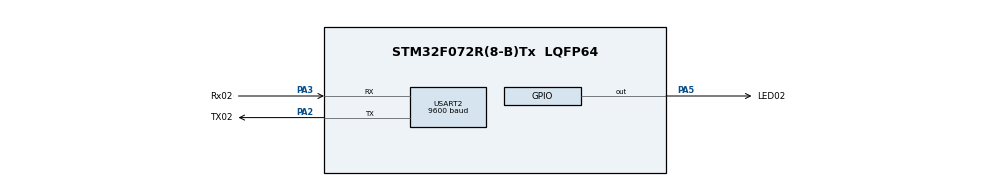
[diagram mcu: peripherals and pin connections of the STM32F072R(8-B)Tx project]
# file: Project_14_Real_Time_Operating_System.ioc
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FREERTOS.Tasks01=Blink01,24,128,StartBlink01,Default,NULL,Dynamic,NULL,NULL;Blink02,16,128,StartBlink02,Default,NULL,Dynamic,NULL,NULL
Mcu.Family=STM32F0
Mcu.Name=STM32F072R(8-B)Tx
Mcu.Package=LQFP64
NVIC.TIM6_DAC_IRQn=true\:3\:0\:false\:false\:true\:false\:false\:true\:true
NVIC.TimeBase=TIM6_DAC_IRQn
NVIC.TimeBaseIP=TIM6
PA2.GPIO_Label=TX02
PA2.Mode=Asynchronous
PA2.Signal=USART2_TX
PA3.GPIO_Label=Rx02
PA3.Mode=Asynchronous
PA3.Signal=USART2_RX
PA5.GPIO_Label=LED02
PA5.Signal=GPIO_Output
ProjectManager.HeapSize=0x200
ProjectManager.StackSize=0x400
ProjectManager.TargetToolchain=STM32CubeIDE
USART2.BaudRate=9600
USART2.VirtualMode-Asynchronous=VM_ASYNC
VP_FREERTOS_VS_CMSIS_V2.Mode=CMSIS_V2
VP_SYS_VS_tim6.Mode=TIM6
board=custom

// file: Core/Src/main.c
/* USER CODE BEGIN Header */
/**
  ******************************************************************************
  * @file           : main.c
  * @brief          : Main program body
  ******************************************************************************
  * @attention
  *
  * Copyright (c) 2022 STMicroelectronics.
  * All rights reserved.
  *
  * This software is licensed under terms that can be found in the LICENSE file
  * in the root directory of this software component.
  * If no LICENSE file comes with this software, it is provided AS-IS.
  *
  ******************************************************************************
  */
/* USER CODE END Header */
#include "main.h"
#include "cmsis_os.h"

UART_HandleTypeDef huart2;

/* Definitions for Blink01 */
osThreadId_t Blink01Handle;
const osThreadAttr_t Blink01_attributes = {
  .name = "Blink01",
  .stack_size = 128 * 4,
  .priority = (osPriority_t) osPriorityNormal,
};
/* Definitions for Blink02 */
osThreadId_t Blink02Handle;
const osThreadAttr_t Blink02_attributes = {
  .name = "Blink02",
  .stack_size = 128 * 4,
  .priority = (osPriority_t) osPriorityBelowNormal,
};

void SystemClock_Config(void);
static void MX_GPIO_Init(void);
static void MX_USART2_UART_Init(void);
void StartBlink01(void *argument);
void StartBlink02(void *argument);

/* USER CODE BEGIN PFP */

void Task_action(char message);

/* USER CODE END PFP */

int main(void)
{

  /* MCU Configuration--------------------------------------------------------*/

  /* Reset of all peripherals, Initializes the Flash interface and the Systick. */
  HAL_Init();

  /* Configure the system clock */
  SystemClock_Config();

  /* Initialize all configured peripherals */
  MX_GPIO_Init();
  MX_USART2_UART_Init();

  /* Init scheduler */
  osKernelInitialize();

  /* Create the thread(s) */
  /* creation of Blink01 */
  Blink01Handle = osThreadNew(StartBlink01, NULL, &Blink01_attributes);

  /* creation of Blink02 */
  Blink02Handle = osThreadNew(StartBlink02, NULL, &Blink02_attributes);

  /* Start scheduler */
  osKernelStart();

  /* We should never get here as control is now taken by the scheduler */
  /* Infinite loop */
  while (1)
  {

  }
}

void SystemClock_Config(void)
{
  RCC_OscInitTypeDef RCC_OscInitStruct = {0};
  RCC_ClkInitTypeDef RCC_ClkInitStruct = {0};
  RCC_PeriphCLKInitTypeDef PeriphClkInit = {0};

  /** Initializes the RCC Oscillators according to the specified parameters
  * in the RCC_OscInitTypeDef structure.
  */
  RCC_OscInitStruct.OscillatorType = RCC_OSCILLATORTYPE_HSI;
  RCC_OscInitStruct.HSIState = RCC_HSI_ON;
  RCC_OscInitStruct.HSICalibrationValue = RCC_HSICALIBRATION_DEFAULT;
  RCC_OscInitStruct.PLL.PLLState = RCC_PLL_NONE;
  if (HAL_RCC_OscConfig(&RCC_OscInitStruct) != HAL_OK)
  {
    Error_Handler();
  }

  /** Initializes the CPU, AHB and APB buses clocks
  */
  RCC_ClkInitStruct.ClockType = RCC_CLOCKTYPE_HCLK|RCC_CLOCKTYPE_SYSCLK
                              |RCC_CLOCKTYPE_PCLK1;
  RCC_ClkInitStruct.SYSCLKSource = RCC_SYSCLKSOURCE_HSI;
  RCC_ClkInitStruct.AHBCLKDivider = RCC_SYSCLK_DIV1;
  RCC_ClkInitStruct.APB1CLKDivider = RCC_HCLK_DIV1;

  if (HAL_RCC_ClockConfig(&RCC_ClkInitStruct, FLASH_LATENCY_0) != HAL_OK)
  {
    Error_Handler();
  }
  PeriphClkInit.PeriphClockSelection = RCC_PERIPHCLK_USART2;
  PeriphClkInit.Usart2ClockSelection = RCC_USART2CLKSOURCE_PCLK1;
  if (HAL_RCCEx_PeriphCLKConfig(&PeriphClkInit) != HAL_OK)
  {
    Error_Handler();
  }
}

static void MX_USART2_UART_Init(void)
{

  huart2.Instance = USART2;
  huart2.Init.BaudRate = 9600;
  huart2.Init.WordLength = UART_WORDLENGTH_8B;
  huart2.Init.StopBits = UART_STOPBITS_1;
  huart2.Init.Parity = UART_PARITY_NONE;
  huart2.Init.Mode = UART_MODE_TX_RX;
  huart2.Init.HwFlowCtl = UART_HWCONTROL_NONE;
  huart2.Init.OverSampling = UART_OVERSAMPLING_16;
  huart2.Init.OneBitSampling = UART_ONE_BIT_SAMPLE_DISABLE;
  huart2.AdvancedInit.AdvFeatureInit = UART_ADVFEATURE_NO_INIT;
  if (HAL_UART_Init(&huart2) != HAL_OK)
  {
    Error_Handler();
  }

}

static void MX_GPIO_Init(void)
{
  GPIO_InitTypeDef GPIO_InitStruct = {0};

  /* GPIO Ports Clock Enable */
  __HAL_RCC_GPIOA_CLK_ENABLE();

  /*Configure GPIO pin Output Level */
  HAL_GPIO_WritePin(LED02_GPIO_Port, LED02_Pin, GPIO_PIN_RESET);

  /*Configure GPIO pin : LED02_Pin */
  GPIO_InitStruct.Pin = LED02_Pin;
  GPIO_InitStruct.Mode = GPIO_MODE_OUTPUT_PP;
  GPIO_InitStruct.Pull = GPIO_NOPULL;
  GPIO_InitStruct.Speed = GPIO_SPEED_FREQ_LOW;
  HAL_GPIO_Init(LED02_GPIO_Port, &GPIO_InitStruct);

}

/* USER CODE BEGIN 4 */

void Task_aciotn(char message)
{

 uint8_t data[] = {message,'\n','\r'};
 HAL_UART_Transmit(&huart2,data,3,2);

}

/* USER CODE END 4 */

void StartBlink01(void *argument)
{
  /* USER CODE BEGIN 5 */
  /* Infinite loop */
  for(;;)
  {
	HAL_GPIO_TogglePin(GPIOA, GPIO_PIN_5);
    osDelay(1);
  }
  /* USER CODE END 5 */
  osThreadTerminate(NULL);
}

void StartBlink02(void *argument)
{
  /* USER CODE BEGIN StartBlink02 */
  /* Infinite loop */
  for(;;)
  {
	  HAL_GPIO_TogglePin(GPIOA, GPIO_PIN_5);
	  osDelay(1);
  }
  /* USER CODE END StartBlink02 */
  osThreadTerminate(NULL);
}

void HAL_TIM_PeriodElapsedCallback(TIM_HandleTypeDef *htim)
{
  if (htim->Instance == TIM6) {
    HAL_IncTick();
  }
}

void Error_Handler(void)
{
  __disable_irq();
  while (1)
  {
  }
}
